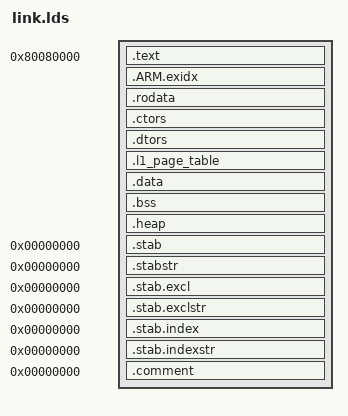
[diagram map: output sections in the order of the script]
OUTPUT_FORMAT("elf32-littlearm", "elf32-littlearm", "elf32-littlearm")
OUTPUT_ARCH(arm)

ENTRY(_boot)

SECTIONS
{
    . = 0x80080000;

    .text :
    {

        *(.boot)
        . = ALIGN(64);
        
        *(.vectors)
        *(.text)
        *(.text.*)

        /* section information for utest */
        . = ALIGN(4);
        __rt_utest_tc_tab_start = .;
        KEEP(*(UtestTcTab))
        __rt_utest_tc_tab_end = .;


        /* section information for finsh shell */
        . = ALIGN(4);
        __fsymtab_start = .;
        KEEP(*(FSymTab))
        __fsymtab_end = .;
        . = ALIGN(4);
        __vsymtab_start = .;
        KEEP(*(VSymTab))
        __vsymtab_end = .;
        . = ALIGN(4);

        /* section information for modules */
        . = ALIGN(4);
        __rtmsymtab_start = .;
        KEEP(*(RTMSymTab))
        __rtmsymtab_end = .;

        /* section information for initialization */
        . = ALIGN(4);
        __rt_init_start = .;
        KEEP(*(SORT(.rti_fn*)))
        __rt_init_end = .;

        /* section information for usb usbh_class_info */
        . = ALIGN(4);
        __usbh_class_info_start__ = .;
        KEEP(*(.usbh_class_info))
        . = ALIGN(4);
        __usbh_class_info_end__ = .;
    } =0
    __text_end = .;

    .ARM.exidx   :
    {
        __exidx_start = .;
        *(.ARM.exidx* .gnu.linkonce.armexidx.*)
        __exidx_end = .;
    }

    __rodata_start = .;
    .rodata   : { *(.rodata) *(.rodata.*) }
    __rodata_end = .;

    . = ALIGN(4);
    .ctors :
    {
        PROVIDE(__ctors_start__ = .);
        /* new GCC version uses .init_array */
        KEEP(*(SORT(.init_array.*)))
        KEEP(*(.init_array))
        PROVIDE(__ctors_end__ = .);
    }

    .dtors :
    {
        PROVIDE(__dtors_start__ = .);
        KEEP(*(SORT(.dtors.*)))
        KEEP(*(.dtors))
        PROVIDE(__dtors_end__ = .);
    }

    . = ALIGN(16 * 1024);
    .l1_page_table :
    {
        __l1_page_table_start = .;
        . += 16K;
    }

    . = ALIGN(8);
    __data_start = .;
    .data :
    {
        *(.data)
        *(.data.*)
    }
    __data_end = .;

    . = ALIGN(8);
    __bss_start = .;
    .bss       :
    {
    *(.bss)
    *(.bss.*)
    *(COMMON)
    . = ALIGN(4);
    }
    . = ALIGN(4);
    __bss_end = .;

    .heap :
    {
        . = ALIGN(8);
        __end__ = .;
        PROVIDE(end = .);
        __HeapBase = .;
        . += 0x400;
        __HeapLimit = .;
        __heap_limit = .; /* Add for _sbrk */
    }

    /* Stabs debugging sections.  */
    .stab 0 : { *(.stab) }
    .stabstr 0 : { *(.stabstr) }
    .stab.excl 0 : { *(.stab.excl) }
    .stab.exclstr 0 : { *(.stab.exclstr) }
    .stab.index 0 : { *(.stab.index) }
    .stab.indexstr 0 : { *(.stab.indexstr) }
    .comment 0 : { *(.comment) }

    _end = .;
}
